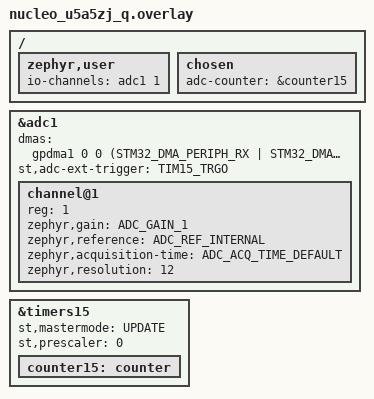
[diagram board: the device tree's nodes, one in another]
/*
 * Copyright (c) 2026 Shontal Biton
 *
 * SPDX-License-Identifier: Apache-2.0
 */

/ {
	zephyr,user {
		io-channels = <&adc1 1>;
	};

	chosen {
		adc-counter = &counter15;
	};
};

&adc1 {
	#address-cells = <1>;
	#size-cells = <0>;

	dmas = <&gpdma1 0 0 (STM32_DMA_PERIPH_RX | STM32_DMA_MEM_16BITS | STM32_DMA_PERIPH_16BITS)>;
	dma-names = "gpdma";
	st,adc-ext-trigger = "TIM15_TRGO";

	channel@1 {
		reg = <1>;
		zephyr,gain = "ADC_GAIN_1";
		zephyr,reference = "ADC_REF_INTERNAL";
		zephyr,acquisition-time = <ADC_ACQ_TIME_DEFAULT>;
		zephyr,resolution = <12>;
	};
};

&timers15 {
	st,mastermode = "UPDATE";
	st,prescaler = <0>;
	status = "okay";

	counter15: counter {
		status = "okay";
	};
};
